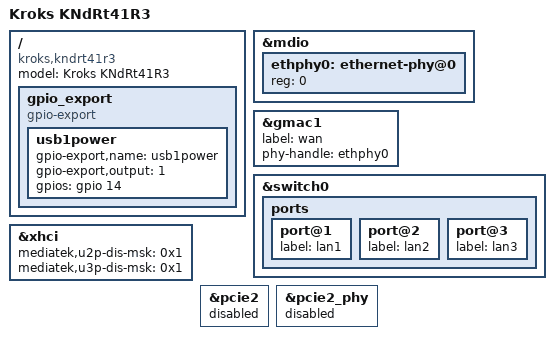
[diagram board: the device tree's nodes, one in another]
#include "mt7621_kroks_wifi_mt7603_mt7613.dtsi"

/ {
	compatible = "kroks,kndrt41r3", "mediatek,mt7621-soc";
	model = "Kroks KNdRt41R3";

	gpio_export {
		compatible = "gpio-export";
		#size-cells = <0>;

		usb1power {
			gpio-export,name = "usb1power";
			gpio-export,output = <1>;
			gpios = <&gpio 14 GPIO_ACTIVE_HIGH>;
		};
	};
};

&mdio {
	ethphy0: ethernet-phy@0 {
		reg = <0>;
	};
};

&gmac1 {
	status = "okay";
	label = "wan";
	phy-handle = <&ethphy0>;
};

&switch0 {
	ports {
		port@1 {
			status = "okay";
			label = "lan1";
		};

		port@2 {
			status = "okay";
			label = "lan2";
		};

		port@3 {
			status = "okay";
			label = "lan3";
		};
	};
};

&xhci {
	mediatek,u2p-dis-msk = <0x1>;
	mediatek,u3p-dis-msk = <0x1>;
};

&pcie2 {
	status = "disabled";
};

&pcie2_phy {
	status = "disabled";
};
